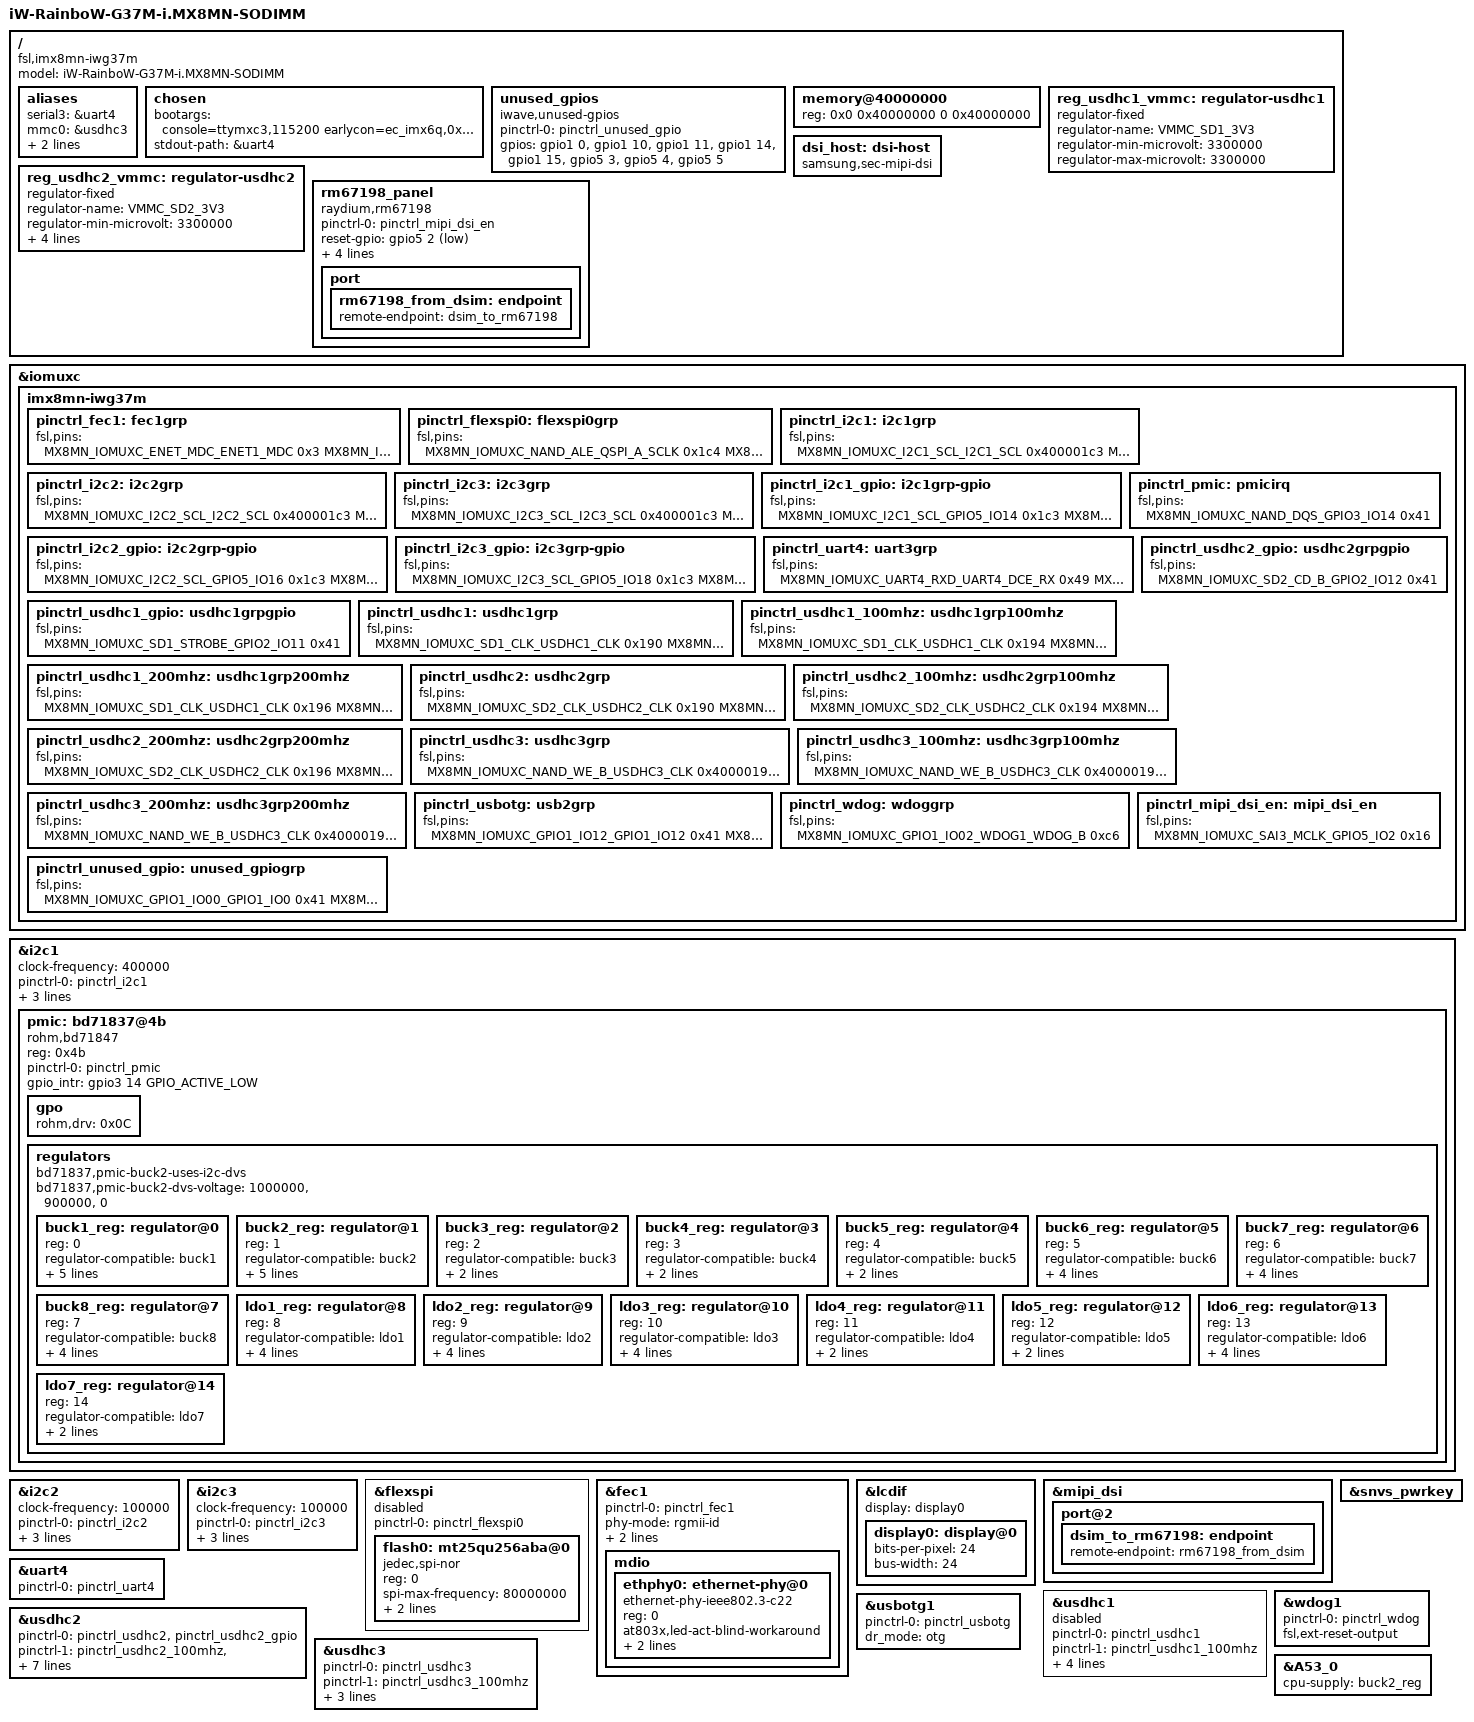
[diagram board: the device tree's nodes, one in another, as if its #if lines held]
// SPDX-License-Identifier: GPL-2.0+
/*
 * Copyright (C) 2020 iWave System Technologies Pvt Ltd.
 */

/dts-v1/;

#include <dt-bindings/usb/pd.h>
#include "imx8mn.dtsi"

/ {
	model = "iW-RainboW-G37M-i.MX8MN-SODIMM";
	compatible = "fsl,imx8mn-iwg37m", "fsl,imx8mn";

	aliases {
                serial3 = &uart4;
                mmc0 = &usdhc3;
                mmc1 = &usdhc2;
                mmc2 = &usdhc1;
        };

	chosen {
		bootargs = "console=ttymxc3,115200 earlycon=ec_imx6q,0x30a60000,115200";
		stdout-path = &uart4;
	};

	unused_gpios: unused_gpios { /* GPIO: Setting unused GPIOs as input pins */
		compatible = "iwave,unused-gpios";
		pinctrl-names = "default";
		pinctrl-0 = <&pinctrl_unused_gpio>;
		status= "okay";
	};

#ifdef CONFIG_SDRAM_SIZE_1GB /* RAM:1GB Memory support */
	memory@40000000 {
        	device_type = "memory";
        	reg = <0x0 0x40000000 0 0x40000000>;
	};
#endif
	reg_usdhc1_vmmc: regulator-usdhc1 { /* USDHC1: SOM Micro SD: 3.3V Fixed Regulator */
		compatible = "regulator-fixed";
		regulator-name = "VMMC_SD1_3V3";
		regulator-min-microvolt = <3300000>;
		regulator-max-microvolt = <3300000>;
	};

	reg_usdhc2_vmmc: regulator-usdhc2 { /* USDHC2: Carrier Micro SD: 3.3V Fixed Regulator */
		compatible = "regulator-fixed";
		regulator-name = "VMMC_SD2_3V3";
		regulator-min-microvolt = <3300000>;
		regulator-max-microvolt = <3300000>;
		enable-active-high;
		startup-delay-us = <100>;
		off-on-delay-us = <12000>;
	};

	dsi_host: dsi-host {
		compatible = "samsung,sec-mipi-dsi";
		status = "okay";
	};

	rm67198_panel {
		compatible = "raydium,rm67198";
		pinctrl-names = "default";
		pinctrl-0 = <&pinctrl_mipi_dsi_en>;
		reset-gpio = <&gpio5 2 GPIO_ACTIVE_LOW>;
		dsi-lanes = <4>;
		video-mode = <2>;	/* 0: burst mode
					 * 1: non-burst mode with sync event
					 * 2: non-burst mode with sync pulse
					 */
		panel-width-mm = <68>;
		panel-height-mm = <121>;
		status = "okay";

		port {
			rm67198_from_dsim: endpoint {
				remote-endpoint = <&dsim_to_rm67198>;
			};
		};
	};
};

&iomuxc {
	pinctrl-names = "default";

	imx8mn-iwg37m {

		pinctrl_fec1: fec1grp { /*Ethernet: IOMUX Pin Configuration */
			fsl,pins = <
				MX8MN_IOMUXC_ENET_MDC_ENET1_MDC			0x3
				MX8MN_IOMUXC_ENET_MDIO_ENET1_MDIO		0x3
				MX8MN_IOMUXC_ENET_TD3_ENET1_RGMII_TD3		0x1f
				MX8MN_IOMUXC_ENET_TD2_ENET1_RGMII_TD2		0x1f
				MX8MN_IOMUXC_ENET_TD1_ENET1_RGMII_TD1		0x1f
				MX8MN_IOMUXC_ENET_TD0_ENET1_RGMII_TD0		0x1f
				MX8MN_IOMUXC_ENET_RD3_ENET1_RGMII_RD3		0x91
				MX8MN_IOMUXC_ENET_RD2_ENET1_RGMII_RD2		0x91
				MX8MN_IOMUXC_ENET_RD1_ENET1_RGMII_RD1		0x91
				MX8MN_IOMUXC_ENET_RD0_ENET1_RGMII_RD0		0x91
				MX8MN_IOMUXC_ENET_TXC_ENET1_RGMII_TXC		0x1f
				MX8MN_IOMUXC_ENET_RXC_ENET1_RGMII_RXC		0x91
				MX8MN_IOMUXC_ENET_RX_CTL_ENET1_RGMII_RX_CTL	0x91
				MX8MN_IOMUXC_ENET_TX_CTL_ENET1_RGMII_TX_CTL	0x1f
				MX8MN_IOMUXC_SAI3_RXFS_GPIO4_IO28		0x19 /* Ethernet Reset GPIO */
			>;
		};

		pinctrl_flexspi0: flexspi0grp { /* QSPI: IOMUX Pin Configuration */
			fsl,pins = <
				MX8MN_IOMUXC_NAND_ALE_QSPI_A_SCLK 		0x1c4
				MX8MN_IOMUXC_NAND_CE0_B_QSPI_A_SS0_B 		0x84
				MX8MN_IOMUXC_NAND_DQS_QSPI_A_DQS 		0x40000084
				MX8MN_IOMUXC_NAND_DATA00_QSPI_A_DATA0 		0x84
				MX8MN_IOMUXC_NAND_DATA01_QSPI_A_DATA1 		0x84
				MX8MN_IOMUXC_NAND_DATA02_QSPI_A_DATA2 		0x84
				MX8MN_IOMUXC_NAND_DATA03_QSPI_A_DATA3 		0x84
			>;
		};

		pinctrl_i2c1: i2c1grp { /* I2C1: I2C IOMUX Pin Configuration */
			fsl,pins = <
				MX8MN_IOMUXC_I2C1_SCL_I2C1_SCL			0x400001c3
				MX8MN_IOMUXC_I2C1_SDA_I2C1_SDA			0x400001c3
			>;
		};

		pinctrl_i2c2: i2c2grp {
                        fsl,pins = <
                                MX8MN_IOMUXC_I2C2_SCL_I2C2_SCL                  0x400001c3
                                MX8MN_IOMUXC_I2C2_SDA_I2C2_SDA                  0x400001c3
                        >;
                };

		pinctrl_i2c3: i2c3grp { /* I2C3: I2C IOMUX Pin Configuration */
			fsl,pins = <
				MX8MN_IOMUXC_I2C3_SCL_I2C3_SCL			0x400001c3
				MX8MN_IOMUXC_I2C3_SDA_I2C3_SDA			0x400001c3
			>;
		};

		pinctrl_i2c1_gpio: i2c1grp-gpio { /* I2C1: I2C GPIO IOMUX Pin Configuration */
			fsl,pins = <
				MX8MN_IOMUXC_I2C1_SCL_GPIO5_IO14        	0x1c3
				MX8MN_IOMUXC_I2C1_SDA_GPIO5_IO15        	0x1c3
			>;
		};

		pinctrl_i2c2_gpio: i2c2grp-gpio {
                        fsl,pins = <
                                MX8MN_IOMUXC_I2C2_SCL_GPIO5_IO16                0x1c3
                                MX8MN_IOMUXC_I2C2_SDA_GPIO5_IO17                0x1c3
                        >;
                };

		pinctrl_i2c3_gpio: i2c3grp-gpio { /* I2C3: I2C GPIO IOMUX Pin Configuration */
			fsl,pins = <
				MX8MN_IOMUXC_I2C3_SCL_GPIO5_IO18        	0x1c3
				MX8MN_IOMUXC_I2C3_SDA_GPIO5_IO19        	0x1c3
			>;
		};

		pinctrl_pmic: pmicirq { /* PMIC: PMIC IOMUX Pin Configuration */
			fsl,pins = <
				MX8MN_IOMUXC_NAND_DQS_GPIO3_IO14		0x41
			>;
		};

		pinctrl_uart4: uart3grp { /* UART4: Debug UART IOMUX Pin Configuration */
			fsl,pins = <
				MX8MN_IOMUXC_UART4_RXD_UART4_DCE_RX		0x49
				MX8MN_IOMUXC_UART4_TXD_UART4_DCE_TX		0x49
			>;
		};

		pinctrl_usdhc1_gpio: usdhc1grpgpio {
			fsl,pins = <    
				MX8MN_IOMUXC_SD1_STROBE_GPIO2_IO11       	0x41
			>;
		};

		pinctrl_usdhc1: usdhc1grp { /* USDHC1: SOM Micro SD/WiFi: IOMUX Pin Configuration */
			fsl,pins = <
				MX8MN_IOMUXC_SD1_CLK_USDHC1_CLK			0x190
				MX8MN_IOMUXC_SD1_CMD_USDHC1_CMD			0x1d0
				MX8MN_IOMUXC_SD1_DATA0_USDHC1_DATA0		0x1d0
				MX8MN_IOMUXC_SD1_DATA1_USDHC1_DATA1		0x1d0
				MX8MN_IOMUXC_SD1_DATA2_USDHC1_DATA2    		0x1d0
				MX8MN_IOMUXC_SD1_DATA3_USDHC1_DATA3		0x1d0
				MX8MN_IOMUXC_GPIO1_IO03_GPIO1_IO3		0x16
			>;
		};

		pinctrl_usdhc1_100mhz: usdhc1grp100mhz {
			fsl,pins = <
				MX8MN_IOMUXC_SD1_CLK_USDHC1_CLK			0x194
				MX8MN_IOMUXC_SD1_CMD_USDHC1_CMD        		0x1d4
				MX8MN_IOMUXC_SD1_DATA0_USDHC1_DATA0    		0x1d4
				MX8MN_IOMUXC_SD1_DATA1_USDHC1_DATA1    		0x1d4
				MX8MN_IOMUXC_SD1_DATA2_USDHC1_DATA2    		0x1d4
				MX8MN_IOMUXC_SD1_DATA3_USDHC1_DATA3    		0x1d4
				MX8MN_IOMUXC_GPIO1_IO03_GPIO1_IO3      		0x16
			>;
		};

		pinctrl_usdhc1_200mhz: usdhc1grp200mhz {
			fsl,pins = <
				MX8MN_IOMUXC_SD1_CLK_USDHC1_CLK        		0x196
				MX8MN_IOMUXC_SD1_CMD_USDHC1_CMD        		0x1d6
				MX8MN_IOMUXC_SD1_DATA0_USDHC1_DATA0    		0x1d6
				MX8MN_IOMUXC_SD1_DATA1_USDHC1_DATA1    		0x1d6
				MX8MN_IOMUXC_SD1_DATA2_USDHC1_DATA2    		0x1d6
				MX8MN_IOMUXC_SD1_DATA3_USDHC1_DATA3    		0x1d6
				MX8MN_IOMUXC_GPIO1_IO03_GPIO1_IO3      		0x16
			>;
		};

		pinctrl_usdhc2_gpio: usdhc2grpgpio {
			fsl,pins = <
				MX8MN_IOMUXC_SD2_CD_B_GPIO2_IO12		0x41
			>;
		};

		pinctrl_usdhc2: usdhc2grp { /* USDHC2: Carrier Micro SD: IOMUX Pin Configuration */
			fsl,pins = <
				MX8MN_IOMUXC_SD2_CLK_USDHC2_CLK			0x190
				MX8MN_IOMUXC_SD2_CMD_USDHC2_CMD			0x1d0
				MX8MN_IOMUXC_SD2_DATA0_USDHC2_DATA0		0x1d0
				MX8MN_IOMUXC_SD2_DATA1_USDHC2_DATA1		0x1d0
				MX8MN_IOMUXC_SD2_DATA2_USDHC2_DATA2		0x1d0
				MX8MN_IOMUXC_SD2_DATA3_USDHC2_DATA3		0x1d0
				MX8MN_IOMUXC_GPIO1_IO04_USDHC2_VSELECT		0x1d0
			>;
		};

		pinctrl_usdhc2_100mhz: usdhc2grp100mhz {
			fsl,pins = <
				MX8MN_IOMUXC_SD2_CLK_USDHC2_CLK			0x194
				MX8MN_IOMUXC_SD2_CMD_USDHC2_CMD			0x1d4
				MX8MN_IOMUXC_SD2_DATA0_USDHC2_DATA0		0x1d4
				MX8MN_IOMUXC_SD2_DATA1_USDHC2_DATA1		0x1d4
				MX8MN_IOMUXC_SD2_DATA2_USDHC2_DATA2		0x1d4
				MX8MN_IOMUXC_SD2_DATA3_USDHC2_DATA3		0x1d4
				MX8MN_IOMUXC_GPIO1_IO04_USDHC2_VSELECT		0x1d0
			>;
		};

		pinctrl_usdhc2_200mhz: usdhc2grp200mhz {
			fsl,pins = <
				MX8MN_IOMUXC_SD2_CLK_USDHC2_CLK			0x196
				MX8MN_IOMUXC_SD2_CMD_USDHC2_CMD			0x1d6
				MX8MN_IOMUXC_SD2_DATA0_USDHC2_DATA0		0x1d6
				MX8MN_IOMUXC_SD2_DATA1_USDHC2_DATA1		0x1d6
				MX8MN_IOMUXC_SD2_DATA2_USDHC2_DATA2		0x1d6
				MX8MN_IOMUXC_SD2_DATA3_USDHC2_DATA3		0x1d6
				MX8MN_IOMUXC_GPIO1_IO04_USDHC2_VSELECT		0x1d0
			>;
		};

		pinctrl_usdhc3: usdhc3grp { /* USDHC3: EMMC: IOMUX Pin Configuration */
			fsl,pins = <
				MX8MN_IOMUXC_NAND_WE_B_USDHC3_CLK		0x40000190
				MX8MN_IOMUXC_NAND_WP_B_USDHC3_CMD		0x1d0
				MX8MN_IOMUXC_NAND_DATA04_USDHC3_DATA0		0x1d0
				MX8MN_IOMUXC_NAND_DATA05_USDHC3_DATA1		0x1d0
				MX8MN_IOMUXC_NAND_DATA06_USDHC3_DATA2		0x1d0
				MX8MN_IOMUXC_NAND_DATA07_USDHC3_DATA3		0x1d0
				MX8MN_IOMUXC_NAND_RE_B_USDHC3_DATA4		0x1d0
				MX8MN_IOMUXC_NAND_CE2_B_USDHC3_DATA5		0x1d0
				MX8MN_IOMUXC_NAND_CE3_B_USDHC3_DATA6		0x1d0
				MX8MN_IOMUXC_NAND_CLE_USDHC3_DATA7		0x1d0
				MX8MN_IOMUXC_NAND_READY_B_USDHC3_RESET_B	0x1d0
				MX8MN_IOMUXC_NAND_CE1_B_USDHC3_STROBE 		0x190
			>;
		};

		pinctrl_usdhc3_100mhz: usdhc3grp100mhz {
			fsl,pins = <
				MX8MN_IOMUXC_NAND_WE_B_USDHC3_CLK		0x40000194
				MX8MN_IOMUXC_NAND_WP_B_USDHC3_CMD		0x1d4
				MX8MN_IOMUXC_NAND_DATA04_USDHC3_DATA0		0x1d4
				MX8MN_IOMUXC_NAND_DATA05_USDHC3_DATA1		0x1d4
				MX8MN_IOMUXC_NAND_DATA06_USDHC3_DATA2		0x1d4
				MX8MN_IOMUXC_NAND_DATA07_USDHC3_DATA3		0x1d4
				MX8MN_IOMUXC_NAND_RE_B_USDHC3_DATA4		0x1d4
				MX8MN_IOMUXC_NAND_CE2_B_USDHC3_DATA5		0x1d4
				MX8MN_IOMUXC_NAND_CE3_B_USDHC3_DATA6		0x1d4
				MX8MN_IOMUXC_NAND_CLE_USDHC3_DATA7		0x1d4
				MX8MN_IOMUXC_NAND_READY_B_USDHC3_RESET_B	0x1d4
				MX8MN_IOMUXC_NAND_CE1_B_USDHC3_STROBE 		0x194
			>;
		};

		pinctrl_usdhc3_200mhz: usdhc3grp200mhz {
			fsl,pins = <
				MX8MN_IOMUXC_NAND_WE_B_USDHC3_CLK		0x40000196
				MX8MN_IOMUXC_NAND_WP_B_USDHC3_CMD		0x1d6
				MX8MN_IOMUXC_NAND_DATA04_USDHC3_DATA0		0x1d6
				MX8MN_IOMUXC_NAND_DATA05_USDHC3_DATA1		0x1d6
				MX8MN_IOMUXC_NAND_DATA06_USDHC3_DATA2		0x1d6
				MX8MN_IOMUXC_NAND_DATA07_USDHC3_DATA3		0x1d6
				MX8MN_IOMUXC_NAND_RE_B_USDHC3_DATA4		0x1d6
				MX8MN_IOMUXC_NAND_CE2_B_USDHC3_DATA5		0x1d6
				MX8MN_IOMUXC_NAND_CE3_B_USDHC3_DATA6		0x1d6
				MX8MN_IOMUXC_NAND_CLE_USDHC3_DATA7		0x1d6
				MX8MN_IOMUXC_NAND_READY_B_USDHC3_RESET_B	0x1d6
				MX8MN_IOMUXC_NAND_CE1_B_USDHC3_STROBE 		0x196
			>;
		};

		pinctrl_usbotg: usb2grp {  /*USB1: USB OTG IOMUX Pin COnfiguration */
			fsl,pins = <
				MX8MN_IOMUXC_GPIO1_IO12_GPIO1_IO12		0x41
				MX8MN_IOMUXC_GPIO1_IO13_GPIO1_IO13		0x41
			>;
		};

		pinctrl_wdog: wdoggrp { /* WATCHDOG: Watchdog IOMUX Pin COnfiguration */
			fsl,pins = <
				MX8MN_IOMUXC_GPIO1_IO02_WDOG1_WDOG_B		0xc6
			>;
		};

		pinctrl_unused_gpio: unused_gpiogrp{
			fsl,pins = <
				/* GPIO: Unused GPIO IOMUX Pin Configuration */
				MX8MN_IOMUXC_GPIO1_IO00_GPIO1_IO0		0x41
				MX8MN_IOMUXC_GPIO1_IO10_GPIO1_IO10		0x41
				MX8MN_IOMUXC_GPIO1_IO11_GPIO1_IO11		0x41
				MX8MN_IOMUXC_GPIO1_IO14_GPIO1_IO14		0x41
				MX8MN_IOMUXC_GPIO1_IO15_GPIO1_IO15		0x41
				MX8MN_IOMUXC_SPDIF_TX_GPIO5_IO3			0x41
				MX8MN_IOMUXC_SPDIF_RX_GPIO5_IO4			0x41
				MX8MN_IOMUXC_SPDIF_EXT_CLK_GPIO5_IO5		0x41
			>;
		};

		pinctrl_mipi_dsi_en: mipi_dsi_en {
			fsl,pins = <
				MX8MN_IOMUXC_SAI3_MCLK_GPIO5_IO2		0x16
			>;
		};
	};
};

&i2c1 { /* I2C: I2C1 Bus */
	clock-frequency = <400000>;
	pinctrl-names = "default", "gpio";
	pinctrl-0 = <&pinctrl_i2c1>;
	pinctrl-1 = <&pinctrl_i2c1_gpio>;
	scl-gpios = <&gpio5 14 GPIO_ACTIVE_HIGH>;
	sda-gpios = <&gpio5 15 GPIO_ACTIVE_HIGH>;
	status = "okay";

	pmic: bd71837@4b {
		compatible = "rohm,bd71847";
		reg = <0x4b>;
		pinctrl-0 = <&pinctrl_pmic>;
		gpio_intr = <&gpio3 14 GPIO_ACTIVE_LOW>;

		gpo {
			rohm,drv = <0x0C>;	/* 0b0000_1100 all gpos with cmos output mode */
		};

		regulators {
			#address-cells = <1>;
			#size-cells = <0>;

			bd71837,pmic-buck2-uses-i2c-dvs;
			bd71837,pmic-buck2-dvs-voltage = <1000000>, <900000>, <0>; /* VDD_ARM: Run-Idle */

			buck1_reg: regulator@0 {
				reg = <0>;
				regulator-compatible = "buck1";
				regulator-min-microvolt = <700000>;
				regulator-max-microvolt = <1300000>;
				regulator-boot-on;
				regulator-always-on;
				regulator-ramp-delay = <1250>;
			};

			buck2_reg: regulator@1 {
				reg = <1>;
				regulator-compatible = "buck2";
				regulator-min-microvolt = <700000>;
				regulator-max-microvolt = <1300000>;
				regulator-boot-on;
				regulator-always-on;
				regulator-ramp-delay = <1250>;
			};

			buck3_reg: regulator@2 {
				reg = <2>;
				regulator-compatible = "buck3";
				regulator-min-microvolt = <700000>;
				regulator-max-microvolt = <1300000>;
			};

			buck4_reg: regulator@3 {
				reg = <3>;
				regulator-compatible = "buck4";
				regulator-min-microvolt = <700000>;
				regulator-max-microvolt = <1300000>;
			};

			buck5_reg: regulator@4 {
				reg = <4>;
				regulator-compatible = "buck5";
				regulator-min-microvolt = <700000>;
				regulator-max-microvolt = <1350000>;
			};

			buck6_reg: regulator@5 {
				reg = <5>;
				regulator-compatible = "buck6";
				regulator-min-microvolt = <3000000>;
				regulator-max-microvolt = <3300000>;
				regulator-boot-on;
				regulator-always-on;
			};

			buck7_reg: regulator@6 {
				reg = <6>;
				regulator-compatible = "buck7";
				regulator-min-microvolt = <1605000>;
				regulator-max-microvolt = <1995000>;
				regulator-boot-on;
				regulator-always-on;
			};

			buck8_reg: regulator@7 {
				reg = <7>;
				regulator-compatible = "buck8";
				regulator-min-microvolt = <800000>;
				regulator-max-microvolt = <1400000>;
				regulator-boot-on;
				regulator-always-on;
			};

			ldo1_reg: regulator@8 {
				reg = <8>;
				regulator-compatible = "ldo1";
				regulator-min-microvolt = <3000000>;
				regulator-max-microvolt = <3300000>;
				regulator-boot-on;
				regulator-always-on;
			};

			ldo2_reg: regulator@9 {
				reg = <9>;
				regulator-compatible = "ldo2";
				regulator-min-microvolt = <900000>;
				regulator-max-microvolt = <900000>;
				regulator-boot-on;
				regulator-always-on;
			};

			ldo3_reg: regulator@10 {
				reg = <10>;
				regulator-compatible = "ldo3";
				regulator-min-microvolt = <1800000>;
				regulator-max-microvolt = <3300000>;
				regulator-boot-on;
				regulator-always-on;
			};

			ldo4_reg: regulator@11 {
				reg = <11>;
				regulator-compatible = "ldo4";
				regulator-min-microvolt = <900000>;
				regulator-max-microvolt = <1800000>;
			};

			ldo5_reg: regulator@12 {
				reg = <12>;
				regulator-compatible = "ldo5";
				regulator-min-microvolt = <1800000>;
				regulator-max-microvolt = <3300000>;
			};

			ldo6_reg: regulator@13 {
				reg = <13>;
				regulator-compatible = "ldo6";
				regulator-min-microvolt = <900000>;
				regulator-max-microvolt = <1800000>;
				regulator-boot-on;
				regulator-always-on;
			};

			ldo7_reg: regulator@14 {
				reg = <14>;
				regulator-compatible = "ldo7";
				regulator-min-microvolt = <1800000>;
				regulator-max-microvolt = <3300000>;
			};
		};
	};
};

&i2c2 { /* I2C: I2C2 Bus */
	clock-frequency = <100000>;
	pinctrl-names = "default", "gpio";
	pinctrl-0 = <&pinctrl_i2c2>;
	pinctrl-1 = <&pinctrl_i2c2_gpio>;
	scl-gpios = <&gpio5 16 GPIO_ACTIVE_HIGH>;
	sda-gpios = <&gpio5 17 GPIO_ACTIVE_HIGH>;
	status = "okay";
};

&i2c3 { /* I2C: I2C3 Bus */
	clock-frequency = <100000>;
	pinctrl-names = "default", "gpio";
	pinctrl-0 = <&pinctrl_i2c3>;
	pinctrl-1 = <&pinctrl_i2c3_gpio>;
	scl-gpios = <&gpio5 18 GPIO_ACTIVE_HIGH>;
	sda-gpios = <&gpio5 19 GPIO_ACTIVE_HIGH>;
	status = "okay";
};

&flexspi { /* QSPI: SPI */
	pinctrl-names = "default";
	pinctrl-0 = <&pinctrl_flexspi0>;
	status = "disabled";

	flash0: mt25qu256aba@0 {
		reg = <0>;
		compatible = "jedec,spi-nor";
		spi-max-frequency = <80000000>;
		spi-tx-bus-width = <4>;
		spi-rx-bus-width = <4>;
	};
};

&fec1 { /* FEC1: AR8031 PHY ENET */
	pinctrl-names = "default";
	pinctrl-0 = <&pinctrl_fec1>;
	phy-mode = "rgmii-id";
	phy-handle = <&ethphy0>;
	fsl,magic-packet;
	status = "okay";

	mdio {
		#address-cells = <1>;
		#size-cells = <0>;

		ethphy0: ethernet-phy@0 {
			compatible = "ethernet-phy-ieee802.3-c22";
			reg = <0>;
			at803x,led-act-blind-workaround;
			at803x,eee-disabled;
			at803x,vddio-1p8v;
		};
	};
};

&lcdif {
	display = <&display0>;
	status = "okay";

	display0: display@0 {
		bits-per-pixel = <24>;
		bus-width = <24>;
	};
};

&mipi_dsi {
	status = "okay";

	port@2 {
		dsim_to_rm67198: endpoint {
			remote-endpoint = <&rm67198_from_dsim>;
		};
	};
};

&snvs_pwrkey {
	status = "okay";
};

&uart4 { /* Debug Console */
	pinctrl-names = "default";
	pinctrl-0 = <&pinctrl_uart4>;
	status = "okay";
};

&usdhc1 { /* On SOM MSD (Optional) */
	pinctrl-names = "default", "state_100mhz", "state_200mhz";
	pinctrl-0 = <&pinctrl_usdhc1>;
	pinctrl-1 = <&pinctrl_usdhc1_100mhz>;
	pinctrl-2 = <&pinctrl_usdhc1_200mhz>;
	bus-width = <4>;
	vmmc-supply = <&reg_usdhc1_vmmc>;
	cd-gpios = <&gpio2 11 1>;
	status = "disabled";
};

&usdhc2 { /* Carrier MSD */
	pinctrl-names = "default", "state_100mhz", "state_200mhz";
	pinctrl-0 = <&pinctrl_usdhc2>, <&pinctrl_usdhc2_gpio>;
	pinctrl-1 = <&pinctrl_usdhc2_100mhz>, <&pinctrl_usdhc2_gpio>;
	pinctrl-2 = <&pinctrl_usdhc2_200mhz>, <&pinctrl_usdhc2_gpio>;
	cd-gpios = <&gpio2 12 GPIO_ACTIVE_LOW>;
	bus-width = <4>;
	no-1-8-v;
	vmmc-supply = <&reg_usdhc2_vmmc>;
	status = "okay";
};

&usdhc3 { /* eMMC */
	pinctrl-names = "default", "state_100mhz", "state_200mhz";
	pinctrl-0 = <&pinctrl_usdhc3>;
	pinctrl-1 = <&pinctrl_usdhc3_100mhz>;
	pinctrl-2 = <&pinctrl_usdhc3_200mhz>;
	bus-width = <8>;
	non-removable;
	status = "okay";
};

&wdog1 { /* Watchdog */
	pinctrl-names = "default";
	pinctrl-0 = <&pinctrl_wdog>;
	fsl,ext-reset-output;
	status = "okay";
};

&usbotg1 { /* USB1: USB OTG */
        pinctrl-names = "default";
        pinctrl-0 = <&pinctrl_usbotg>;
        dr_mode = "otg";
        status = "okay";
};

&A53_0 { /* A53 CPU */
	cpu-supply = <&buck2_reg>;
};

&unused_gpios { /* GPIO: iWave Unused GPIO pins */ 
	gpios = <&gpio1 0 0>,
		<&gpio1 10 0>,
		<&gpio1 11 0>,
		<&gpio1 14 0>,
		<&gpio1 15 0>,
		<&gpio5 3 0>,
		<&gpio5 4 0>,
		<&gpio5 5 0>;
};
